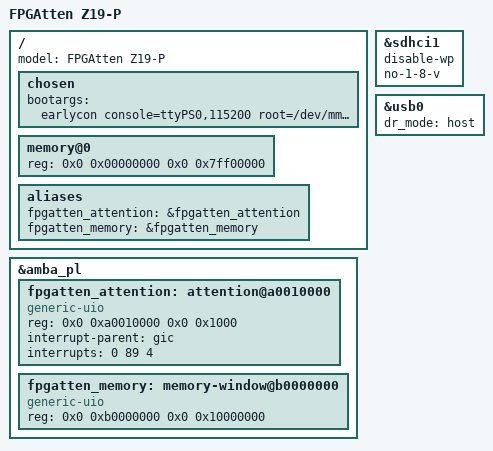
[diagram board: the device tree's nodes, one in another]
/*
 * FPGAtten Z19-P Linux integration.
 *
 * The hardware design and register ABI are inherited unchanged from the
 * verified 235 MHz core / 300 MHz DMA XSA.  This file only replaces the
 * autogenerated PL device names with stable generic-uio nodes and selects
 * the persistent SD-card root filesystem.
 */

/ {
    model = "FPGAtten Z19-P";

    chosen {
        bootargs = "earlycon console=ttyPS0,115200 root=/dev/mmcblk1p2 rootwait rw rootfstype=ext4 maxcpus=1 uio_pdrv_genirq.of_id=generic-uio";
    };

    memory@0 {
        device_type = "memory";
        reg = <0x0 0x00000000 0x0 0x7ff00000>;
    };

    aliases {
        /delete-property/ gqav5_accelerator_0;
        /delete-property/ ps_pl_ddr_rebase_0;
        /delete-property/ gqav5_uio;
        /delete-property/ pl_ddr_uio;
        fpgatten_attention = &fpgatten_attention;
        fpgatten_memory = &fpgatten_memory;
    };
};

&amba_pl {
    /delete-node/ gqav5_vivado_ip_top@a0010000;
    /delete-node/ gqav5_ps_pl_ddr_axi_rebase@b0000000;

    fpgatten_attention: attention@a0010000 {
        compatible = "generic-uio";
        reg = <0x0 0xa0010000 0x0 0x1000>;
        interrupt-parent = <&gic>;
        interrupts = <0 89 4>;
        status = "okay";
    };

    fpgatten_memory: memory-window@b0000000 {
        compatible = "generic-uio";
        reg = <0x0 0xb0000000 0x0 0x10000000>;
        status = "okay";
    };
};

&sdhci1 {
    disable-wp;
    no-1-8-v;
};

&usb0 {
    dr_mode = "host";
};
